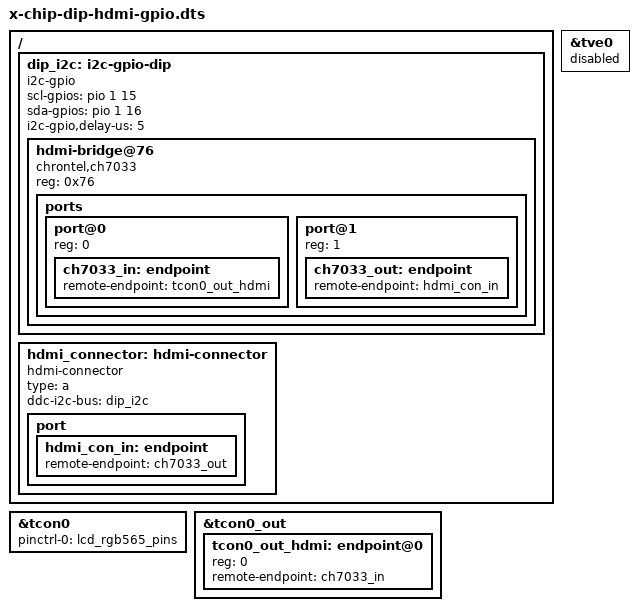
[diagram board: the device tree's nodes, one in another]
// SPDX-License-Identifier: (GPL-2.0 OR MIT)
/*
 * CHIP HDMI DIP -- EXPERIMENTAL i2c-gpio (bitbang) variant of x-chip-dip-hdmi.
 *
 * Why: on hardware (two different HDMI boards) the sunxi mv64xxx i2c controller
 * ACKs the ch7033's address on a write but loses arbitration (status 0x38) the
 * instant it tries to READ the chip, then wedges -- a controller/chip read
 * incompatibility, not bad hardware (the PocketCHIP keyboard on the SAME bus
 * works fine, so i2c1 itself is good). A software bitbang has no mv64xxx FSM and
 * tolerates the ch7033's read/clock-stretch behaviour, so it may succeed where
 * the hardware controller can't.
 *
 * This puts the ch7033 + the connector's DDC on an i2c-gpio bus driven on the
 * SAME physical TWI1 pins (PB15=SCK, PB16=SDA). The hardware i2c@1c2b000 stays
 * disabled (base default) so it doesn't fight for the pins. CONFIG_I2C_GPIO=y.
 *
 * If this works it should replace x-chip-dip-hdmi.dts. If SDA/SCL look swapped
 * (no ACK at all), swap the two *-gpios lines below.
 *
 * IMPORTANT -- the i2c-gpio bus AND the connector are NEW root nodes, so they
 * MUST live in an explicit `fragment { target-path = "/"; ... }`. With the bare
 * `/ { ... }` shorthand dtc leaves them as stray overlay-root nodes that
 * `fdt apply` drops silently -- here that means the ENTIRE HDMI path (bus +
 * ch7033 + connector) vanishes. See the note in x-chip-dip-vga.dts.
 */

/dts-v1/;
/plugin/;

#include <dt-bindings/gpio/gpio.h>

/ {
	/* Route TCON0's parallel RGB565 pins. */
	fragment@0 {
		target = <&tcon0>;
		__overlay__ {
			pinctrl-names = "default";
			pinctrl-0 = <&lcd_rgb565_pins>;
		};
	};

	/* Wire TCON0's RGB output (port@1, channel-0 endpoint) into the ch7033. */
	fragment@1 {
		target = <&tcon0_out>;
		__overlay__ {
			#address-cells = <1>;
			#size-cells = <0>;
			tcon0_out_hdmi: endpoint@0 {
				reg = <0>;
				remote-endpoint = <&ch7033_in>;
			};
		};
	};

	/* Drop the composite (TVE) output so tcon0 drives only the RGB channel. */
	fragment@2 {
		target = <&tve0>;
		__overlay__ {
			status = "disabled";
		};
	};

	/* Bitbang i2c bus + ch7033 + connector, all NEW root nodes -> target-path="/". */
	fragment@3 {
		target-path = "/";
		__overlay__ {
			dip_i2c: i2c-gpio-dip {
				compatible = "i2c-gpio";
				/* TWI1 pins as plain GPIOs: PB15 = SCK, PB16 = SDA (bank B = 1). */
				scl-gpios = <&pio 1 15 (GPIO_ACTIVE_HIGH | GPIO_OPEN_DRAIN)>;
				sda-gpios = <&pio 1 16 (GPIO_ACTIVE_HIGH | GPIO_OPEN_DRAIN)>;
				i2c-gpio,delay-us = <5>;   /* ~100 kHz */
				#address-cells = <1>;
				#size-cells = <0>;

				hdmi-bridge@76 {
					compatible = "chrontel,ch7033";
					reg = <0x76>;

					ports {
						#address-cells = <1>;
						#size-cells = <0>;

						port@0 {
							reg = <0>;
							ch7033_in: endpoint {
								remote-endpoint = <&tcon0_out_hdmi>;
							};
						};

						port@1 {
							reg = <1>;
							ch7033_out: endpoint {
								remote-endpoint = <&hdmi_con_in>;
							};
						};
					};
				};
			};

			hdmi_connector: hdmi-connector {
				compatible = "hdmi-connector";
				type = "a";
				ddc-i2c-bus = <&dip_i2c>;

				port {
					hdmi_con_in: endpoint {
						remote-endpoint = <&ch7033_out>;
					};
				};
			};
		};
	};
};
